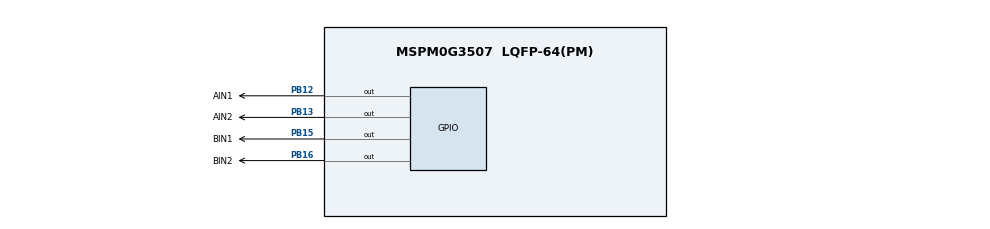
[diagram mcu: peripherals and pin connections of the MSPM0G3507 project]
/**
 * These arguments were used when this file was generated. They will be automatically applied on subsequent loads
 * via the GUI or CLI. Run CLI with '--help' for additional information on how to override these arguments.
 * @cliArgs --device "MSPM0G350X" --part "Default" --package "LQFP-64(PM)" --product "mspm0_sdk@2.10.00.04"
 * @v2CliArgs --device "MSPM0G3507" --package "LQFP-64(PM)" --product "mspm0_sdk@2.10.00.04"
 * @versions {"tool":"1.26.2+4477"}
 */

/**
 * Import the modules used in this configuration.
 */
const GPIO   = scripting.addModule("/ti/driverlib/GPIO", {}, false);
const GPIO1  = GPIO.addInstance();
const GPIO2  = GPIO.addInstance();
const PWM    = scripting.addModule("/ti/driverlib/PWM", {}, false);
const PWM1   = PWM.addInstance();
const SYSCTL = scripting.addModule("/ti/driverlib/SYSCTL");

/**
 * Write custom configuration values to the imported modules.
 */
GPIO1.$name                         = "TB6612_IO";
GPIO1.port                          = "PORTB";
GPIO1.associatedPins.create(4);
GPIO1.associatedPins[0].$name       = "AIN1";
GPIO1.associatedPins[0].assignedPin = "12";
GPIO1.associatedPins[0].pin.$assign = "PB12";
GPIO1.associatedPins[1].$name       = "AIN2";
GPIO1.associatedPins[1].assignedPin = "13";
GPIO1.associatedPins[1].pin.$assign = "PB13";
GPIO1.associatedPins[2].$name       = "BIN1";
GPIO1.associatedPins[2].assignedPin = "15";
GPIO1.associatedPins[2].pin.$assign = "PB15";
GPIO1.associatedPins[3].$name       = "BIN2";
GPIO1.associatedPins[3].assignedPin = "16";
GPIO1.associatedPins[3].pin.$assign = "PB16";

const Board = scripting.addModule("/ti/driverlib/Board", {}, false);

GPIO2.$name                          = "GRAPH_SENSOR";
GPIO2.associatedPins.create(4);
GPIO2.associatedPins[0].$name        = "HW_OUT_1";
GPIO2.associatedPins[0].direction    = "INPUT";
GPIO2.associatedPins[0].assignedPort = "PORTA";
GPIO2.associatedPins[0].assignedPin  = "8";
GPIO2.associatedPins[1].$name        = "HW_OUT_2";
GPIO2.associatedPins[1].direction    = "INPUT";
GPIO2.associatedPins[1].assignedPort = "PORTA";
GPIO2.associatedPins[1].assignedPin  = "18";
GPIO2.associatedPins[2].$name        = "HW_OUT_3";
GPIO2.associatedPins[2].direction    = "INPUT";
GPIO2.associatedPins[2].assignedPort = "PORTA";
GPIO2.associatedPins[2].assignedPin  = "27";
GPIO2.associatedPins[3].$name        = "HW_OUT_4";
GPIO2.associatedPins[3].direction    = "INPUT";
GPIO2.associatedPins[3].assignedPort = "PORTA";
GPIO2.associatedPins[3].assignedPin  = "15";

PWM1.$name                              = "TB6612_PWM";
PWM1.timerCount                         = 3200;
PWM1.pwmMode                            = "EDGE_ALIGN_UP";
PWM1.peripheral.$assign                 = "TIMG0";
PWM1.PWM_CHANNEL_0.$name                = "ti_driverlib_pwm_PWMTimerCC0";
PWM1.PWM_CHANNEL_0.dutyCycle            = 10;
PWM1.PWM_CHANNEL_1.$name                = "ti_driverlib_pwm_PWMTimerCC1";
PWM1.PWM_CHANNEL_1.dutyCycle            = 10;
PWM1.ccp0PinConfig.$name                = "ti_driverlib_gpio_GPIOPinGeneric0";
PWM1.ccp0PinConfig.direction            = scripting.forceWrite("OUTPUT");
PWM1.ccp0PinConfig.hideOutputInversion  = scripting.forceWrite(false);
PWM1.ccp0PinConfig.onlyInternalResistor = scripting.forceWrite(false);
PWM1.ccp0PinConfig.passedPeripheralType = scripting.forceWrite("Digital");
PWM1.ccp1PinConfig.$name                = "ti_driverlib_gpio_GPIOPinGeneric1";
PWM1.ccp1PinConfig.direction            = scripting.forceWrite("OUTPUT");
PWM1.ccp1PinConfig.hideOutputInversion  = scripting.forceWrite(false);
PWM1.ccp1PinConfig.onlyInternalResistor = scripting.forceWrite(false);
PWM1.ccp1PinConfig.passedPeripheralType = scripting.forceWrite("Digital");

SYSCTL.forceDefaultClkConfig = true;
SYSCTL.clockTreeEn           = true;

/**
 * Pinmux solution for unlocked pins/peripherals. This ensures that minor changes to the automatic solver in a future
 * version of the tool will not impact the pinmux you originally saw.  These lines can be completely deleted in order to
 * re-solve from scratch.
 */
Board.peripheral.$suggestSolution            = "DEBUGSS";
Board.peripheral.swclkPin.$suggestSolution   = "PA20";
Board.peripheral.swdioPin.$suggestSolution   = "PA19";
GPIO2.associatedPins[0].pin.$suggestSolution = "PA8";
GPIO2.associatedPins[1].pin.$suggestSolution = "PA18";
GPIO2.associatedPins[2].pin.$suggestSolution = "PA27";
GPIO2.associatedPins[3].pin.$suggestSolution = "PA15";
PWM1.peripheral.ccp0Pin.$suggestSolution     = "PA12";
PWM1.peripheral.ccp1Pin.$suggestSolution     = "PA13";
